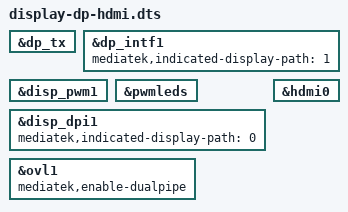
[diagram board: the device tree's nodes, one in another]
/dts-v1/;
/plugin/;

/ {
	fragment@0 {
		target = <&dp_tx>;
		__overlay__ {
			status = "okay";
		};
	};

	fragment@1 {
		target = <&dp_intf1>;
		__overlay__ {
			status = "okay";
			mediatek,indicated-display-path = <1>;
		};
	};

	fragment@2 {
		target = <&disp_pwm1>;
		__overlay__ {
			status = "okay";
		};
	};

	fragment@3 {
		target = <&pwmleds>;
		__overlay__ {
			status = "okay";
		};
	};

	fragment@4 {
		target = <&disp_dpi1>;
		__overlay__ {
			status = "okay";
			mediatek,indicated-display-path = <0>;
		};
	};

	fragment@5 {
		target = <&hdmi0>;
		__overlay__ {
			status = "okay";
		};
	};

	fragment@6 {
		target = <&ovl1>;
		__overlay__ {
			mediatek,enable-dualpipe;
		};
	};
};
